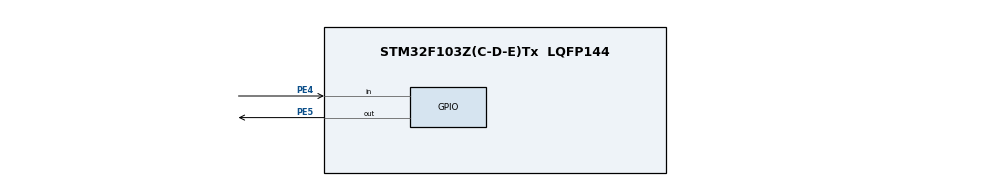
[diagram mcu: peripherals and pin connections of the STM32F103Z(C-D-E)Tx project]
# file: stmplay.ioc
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Mcu.Family=STM32F1
Mcu.Name=STM32F103Z(C-D-E)Tx
Mcu.Package=LQFP144
NVIC.PriorityGroup=NVIC_PRIORITYGROUP_4
PA13.Mode=Trace_Asynchronous_SW
PA13.Signal=SYS_JTMS-SWDIO
PA14.Mode=Trace_Asynchronous_SW
PA14.Signal=SYS_JTCK-SWCLK
PB3.Mode=Trace_Asynchronous_SW
PB3.Signal=SYS_JTDO-TRACESWO
PE4.GPIO_PuPd=GPIO_PULLUP
PE4.Signal=GPIO_Input
PE5.Signal=GPIO_Output
ProjectManager.HeapSize=0xf0ff
ProjectManager.StackSize=0x200
ProjectManager.TargetToolchain=Makefile
RCC.APB1Freq_Value=8000000
RCC.APB2Freq_Value=8000000
board=custom

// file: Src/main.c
/* USER CODE BEGIN Header */
/**
  ******************************************************************************
  * @file           : main.c
  * @brief          : Main program body
  ******************************************************************************
  * @attention
  *
  * <h2><center>&copy; Copyright (c) 2021 STMicroelectronics.
  * All rights reserved.</center></h2>
  *
  * This software component is licensed by ST under BSD 3-Clause license,
  * the "License"; You may not use this file except in compliance with the
  * License. You may obtain a copy of the License at:
  *                        opensource.org/licenses/BSD-3-Clause
  *
  ******************************************************************************
  */
/* USER CODE END Header */
#include "main.h"
#include "mujs.h"
#include "stm32f1xx_hal.h"
#include <stdlib.h>

void SystemClock_Config(void);
static void MX_GPIO_Init(void);

/* USER CODE BEGIN 0 */
static void WritePIN0(js_State *J) {
  HAL_GPIO_WritePin(GPIOE, GPIO_PIN_5, 0);
  js_pushundefined(J);
}
static void WritePIN1(js_State *J) {
  HAL_GPIO_WritePin(GPIOE, GPIO_PIN_5, 1);
  js_pushundefined(J);
}
static void ReadPIN(js_State *J) {
  js_pushboolean(J, HAL_GPIO_ReadPin(GPIOE, GPIO_PIN_4));
}
/* USER CODE END 0 */

int main(void)
{

  /* MCU Configuration--------------------------------------------------------*/

  /* Reset of all peripherals, Initializes the Flash interface and the Systick. */
  HAL_Init();

  /* Configure the system clock */
  SystemClock_Config();

  /* Initialize all configured peripherals */
  MX_GPIO_Init();

  /* Infinite loop */
  /* USER CODE BEGIN WHILE */
  js_State *J = js_newstate(NULL, NULL, JS_STRICT);
  js_newcfunction(J, WritePIN0, "WritePIN0", 0);
  js_setglobal(J, "WritePIN0");
  js_newcfunction(J, WritePIN1, "WritePIN1", 0);
  js_setglobal(J, "WritePIN1");
  js_newcfunction(J, ReadPIN, "ReadPIN", 0);
  js_setglobal(J, "ReadPIN");
  js_dostring(J, "while(true){if(!ReadPIN()){WritePIN0()}else{WritePIN1()}}");
  // while (1)
  // {
  //   Seek_GPIO();
  // }
  /* USER CODE END 3 */
}

void SystemClock_Config(void)
{
  RCC_OscInitTypeDef RCC_OscInitStruct = {0};
  RCC_ClkInitTypeDef RCC_ClkInitStruct = {0};

  /** Initializes the RCC Oscillators according to the specified parameters
  * in the RCC_OscInitTypeDef structure.
  */
  RCC_OscInitStruct.OscillatorType = RCC_OSCILLATORTYPE_HSI;
  RCC_OscInitStruct.HSIState = RCC_HSI_ON;
  RCC_OscInitStruct.HSICalibrationValue = RCC_HSICALIBRATION_DEFAULT;
  RCC_OscInitStruct.PLL.PLLState = RCC_PLL_NONE;
  if (HAL_RCC_OscConfig(&RCC_OscInitStruct) != HAL_OK)
  {
    Error_Handler();
  }
  /** Initializes the CPU, AHB and APB buses clocks
  */
  RCC_ClkInitStruct.ClockType = RCC_CLOCKTYPE_HCLK|RCC_CLOCKTYPE_SYSCLK
                              |RCC_CLOCKTYPE_PCLK1|RCC_CLOCKTYPE_PCLK2;
  RCC_ClkInitStruct.SYSCLKSource = RCC_SYSCLKSOURCE_HSI;
  RCC_ClkInitStruct.AHBCLKDivider = RCC_SYSCLK_DIV1;
  RCC_ClkInitStruct.APB1CLKDivider = RCC_HCLK_DIV1;
  RCC_ClkInitStruct.APB2CLKDivider = RCC_HCLK_DIV1;

  if (HAL_RCC_ClockConfig(&RCC_ClkInitStruct, FLASH_LATENCY_0) != HAL_OK)
  {
    Error_Handler();
  }
}

static void MX_GPIO_Init(void)
{
  GPIO_InitTypeDef GPIO_InitStruct = {0};

  /* GPIO Ports Clock Enable */
  __HAL_RCC_GPIOE_CLK_ENABLE();

  /*Configure GPIO pin Output Level */
  HAL_GPIO_WritePin(GPIOE, GPIO_PIN_5, GPIO_PIN_RESET);

  /*Configure GPIO pin : PE4 */
  GPIO_InitStruct.Pin = GPIO_PIN_4;
  GPIO_InitStruct.Mode = GPIO_MODE_INPUT;
  GPIO_InitStruct.Pull = GPIO_PULLUP;
  HAL_GPIO_Init(GPIOE, &GPIO_InitStruct);

  /*Configure GPIO pin : PE5 */
  GPIO_InitStruct.Pin = GPIO_PIN_5;
  GPIO_InitStruct.Mode = GPIO_MODE_OUTPUT_PP;
  GPIO_InitStruct.Pull = GPIO_NOPULL;
  GPIO_InitStruct.Speed = GPIO_SPEED_FREQ_LOW;
  HAL_GPIO_Init(GPIOE, &GPIO_InitStruct);

}

void Error_Handler(void)
{
  __disable_irq();
  while (1)
  {
  }
}

/************************ (C) COPYRIGHT STMicroelectronics *****END OF FILE****/
